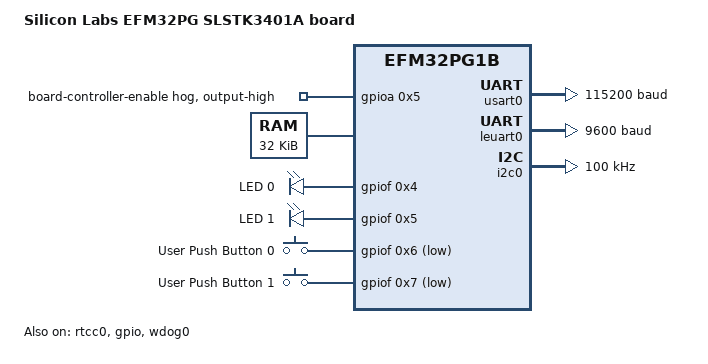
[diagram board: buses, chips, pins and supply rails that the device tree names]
/dts-v1/;

/* node '/' defined in zephyr/dts/common/skeleton.dtsi:9 */
/ {
	#address-cells = < 0x1 >;                        /* in zephyr/dts/common/skeleton.dtsi:10 */
	#size-cells = < 0x1 >;                           /* in zephyr/dts/common/skeleton.dtsi:11 */
	model = "Silicon Labs EFM32PG SLSTK3401A board"; /* in zephyr/boards/silabs/starter_kits/slstk3401a/slstk3401a.dts:12 */
	compatible = "silabs,slstk3401a",
	             "silabs,efm32pg1b";                 /* in zephyr/boards/silabs/starter_kits/slstk3401a/slstk3401a.dts:13 */

	/* node '/chosen' defined in zephyr/dts/common/skeleton.dtsi:13 */
	chosen {
		zephyr,flash-controller = &msc; /* in zephyr/dts/arm/silabs/xg1/xg1.dtsi:10 */
		zephyr,console = &usart0;       /* in zephyr/boards/silabs/starter_kits/slstk3401a/slstk3401a-common.dtsi:14 */
		zephyr,flash = &flash0;         /* in zephyr/boards/silabs/starter_kits/slstk3401a/slstk3401a-common.dtsi:15 */
		zephyr,shell-uart = &usart0;    /* in zephyr/boards/silabs/starter_kits/slstk3401a/slstk3401a-common.dtsi:16 */
		zephyr,sram = &sram0;           /* in zephyr/boards/silabs/starter_kits/slstk3401a/slstk3401a-common.dtsi:17 */
	};

	/* node '/aliases' defined in zephyr/dts/common/skeleton.dtsi:15 */
	aliases {
		led0 = &led0;       /* in zephyr/boards/silabs/starter_kits/slstk3401a/slstk3401a-common.dtsi:22 */
		led1 = &led1;       /* in zephyr/boards/silabs/starter_kits/slstk3401a/slstk3401a-common.dtsi:23 */
		sw0 = &button0;     /* in zephyr/boards/silabs/starter_kits/slstk3401a/slstk3401a-common.dtsi:24 */
		sw1 = &button1;     /* in zephyr/boards/silabs/starter_kits/slstk3401a/slstk3401a-common.dtsi:25 */
		watchdog0 = &wdog0; /* in zephyr/boards/silabs/starter_kits/slstk3401a/slstk3401a-common.dtsi:26 */
	};

	/* node '/soc' defined in zephyr/dts/arm/armv7-m.dtsi:6 */
	soc {
		#address-cells = < 0x1 >;                   /* in zephyr/dts/arm/armv7-m.dtsi:7 */
		#size-cells = < 0x1 >;                      /* in zephyr/dts/arm/armv7-m.dtsi:8 */
		interrupt-parent = < &nvic >;               /* in zephyr/dts/arm/armv7-m.dtsi:10 */
		ranges;                                     /* in zephyr/dts/arm/armv7-m.dtsi:11 */
		compatible = "silabs,efm32pg1b200f256gm48",
		             "silabs,efm32pg1b",
		             "silabs,efm32",
		             "simple-bus";                  /* in zephyr/dts/arm/silabs/xg1/efm32pg1b200f256gm48.dtsi:12 */

		/* node '/soc/interrupt-controller@e000e100' defined in zephyr/dts/arm/armv7-m.dtsi:13 */
		nvic: interrupt-controller@e000e100 {
			#address-cells = < 0x1 >;            /* in zephyr/dts/arm/armv7-m.dtsi:14 */
			compatible = "arm,v7m-nvic";         /* in zephyr/dts/arm/armv7-m.dtsi:15 */
			reg = < 0xe000e100 0xc00 >;          /* in zephyr/dts/arm/armv7-m.dtsi:16 */
			interrupt-controller;                /* in zephyr/dts/arm/armv7-m.dtsi:17 */
			#interrupt-cells = < 0x2 >;          /* in zephyr/dts/arm/armv7-m.dtsi:18 */
			arm,num-irq-priority-bits = < 0x3 >; /* in zephyr/dts/arm/silabs/xg1/xg1.dtsi:184 */
			phandle = < 0x1 >;                   /* in zephyr/dts/arm/armv7-m.dtsi:10 */
		};

		/* node '/soc/timer@e000e010' defined in zephyr/dts/arm/armv7-m.dtsi:21 */
		systick: timer@e000e010 {
			compatible = "arm,armv7m-systick"; /* in zephyr/dts/arm/armv7-m.dtsi:22 */
			reg = < 0xe000e010 0x10 >;         /* in zephyr/dts/arm/armv7-m.dtsi:23 */
		};

		/* node '/soc/flash-controller@400e0000' defined in zephyr/dts/arm/silabs/xg1/xg1.dtsi:28 */
		msc: flash-controller@400e0000 {
			compatible = "silabs,gecko-flash-controller"; /* in zephyr/dts/arm/silabs/xg1/xg1.dtsi:29 */
			reg = < 0x400e0000 0x800 >;                   /* in zephyr/dts/arm/silabs/xg1/xg1.dtsi:30 */
			interrupts = < 0x18 0x0 >;                    /* in zephyr/dts/arm/silabs/xg1/xg1.dtsi:31 */
			#address-cells = < 0x1 >;                     /* in zephyr/dts/arm/silabs/xg1/xg1.dtsi:33 */
			#size-cells = < 0x1 >;                        /* in zephyr/dts/arm/silabs/xg1/xg1.dtsi:34 */

			/* node '/soc/flash-controller@400e0000/flash@0' defined in zephyr/dts/arm/silabs/xg1/xg1.dtsi:36 */
			flash0: flash@0 {
				compatible = "soc-nv-flash";  /* in zephyr/dts/arm/silabs/xg1/xg1.dtsi:37 */
				write-block-size = < 0x4 >;   /* in zephyr/dts/arm/silabs/xg1/xg1.dtsi:38 */
				erase-block-size = < 0x800 >; /* in zephyr/dts/arm/silabs/xg1/xg1.dtsi:39 */
				reg = < 0x0 0x40000 >;        /* in zephyr/dts/arm/silabs/xg1/efm32pg1b200f256gm48.dtsi:17 */

				/* node '/soc/flash-controller@400e0000/flash@0/partitions' defined in zephyr/boards/silabs/starter_kits/slstk3401a/slstk3401a-common.dtsi:127 */
				partitions {
					compatible = "fixed-partitions"; /* in zephyr/boards/silabs/starter_kits/slstk3401a/slstk3401a-common.dtsi:128 */
					#address-cells = < 0x1 >;        /* in zephyr/boards/silabs/starter_kits/slstk3401a/slstk3401a-common.dtsi:129 */
					#size-cells = < 0x1 >;           /* in zephyr/boards/silabs/starter_kits/slstk3401a/slstk3401a-common.dtsi:130 */

					/* node '/soc/flash-controller@400e0000/flash@0/partitions/partition@3e800' defined in zephyr/boards/silabs/starter_kits/slstk3401a/slstk3401a-common.dtsi:133 */
					storage_partition: partition@3e800 {
						reg = < 0x3e800 0x1800 >; /* in zephyr/boards/silabs/starter_kits/slstk3401a/slstk3401a-common.dtsi:134 */
						label = "storage";        /* in zephyr/boards/silabs/starter_kits/slstk3401a/slstk3401a-common.dtsi:135 */
					};
				};
			};
		};

		/* node '/soc/usart@40010000' defined in zephyr/dts/arm/silabs/xg1/xg1.dtsi:43 */
		usart0: usart@40010000 {
			compatible = "silabs,gecko-usart"; /* in zephyr/dts/arm/silabs/xg1/xg1.dtsi:44 */
			reg = < 0x40010000 0x400 >;        /* in zephyr/dts/arm/silabs/xg1/xg1.dtsi:45 */
			interrupts = < 0xb 0x0 >,
			             < 0xc 0x0 >;          /* in zephyr/dts/arm/silabs/xg1/xg1.dtsi:46 */
			interrupt-names = "rx",
			                  "tx";            /* in zephyr/dts/arm/silabs/xg1/xg1.dtsi:47 */
			peripheral-id = < 0x0 >;           /* in zephyr/dts/arm/silabs/xg1/xg1.dtsi:48 */
			current-speed = < 0x1c200 >;       /* in zephyr/boards/silabs/starter_kits/slstk3401a/slstk3401a-common.dtsi:67 */
			pinctrl-0 = < &usart0_default >;   /* in zephyr/boards/silabs/starter_kits/slstk3401a/slstk3401a-common.dtsi:68 */
			pinctrl-names = "default";         /* in zephyr/boards/silabs/starter_kits/slstk3401a/slstk3401a-common.dtsi:69 */
			status = "okay";                   /* in zephyr/boards/silabs/starter_kits/slstk3401a/slstk3401a-common.dtsi:70 */
		};

		/* node '/soc/usart@40010400' defined in zephyr/dts/arm/silabs/xg1/xg1.dtsi:52 */
		usart1: usart@40010400 {
			compatible = "silabs,gecko-usart"; /* in zephyr/dts/arm/silabs/xg1/xg1.dtsi:53 */
			reg = < 0x40010400 0x400 >;        /* in zephyr/dts/arm/silabs/xg1/xg1.dtsi:54 */
			interrupts = < 0x13 0x0 >,
			             < 0x14 0x0 >;         /* in zephyr/dts/arm/silabs/xg1/xg1.dtsi:55 */
			interrupt-names = "rx",
			                  "tx";            /* in zephyr/dts/arm/silabs/xg1/xg1.dtsi:56 */
			peripheral-id = < 0x1 >;           /* in zephyr/dts/arm/silabs/xg1/xg1.dtsi:57 */
			status = "disabled";               /* in zephyr/dts/arm/silabs/xg1/xg1.dtsi:58 */
		};

		/* node '/soc/leuart@4004a000' defined in zephyr/dts/arm/silabs/xg1/xg1.dtsi:61 */
		leuart0: leuart@4004a000 {
			compatible = "silabs,gecko-leuart"; /* in zephyr/dts/arm/silabs/xg1/xg1.dtsi:62 */
			reg = < 0x4004a000 0x400 >;         /* in zephyr/dts/arm/silabs/xg1/xg1.dtsi:63 */
			interrupts = < 0x15 0x0 >;          /* in zephyr/dts/arm/silabs/xg1/xg1.dtsi:64 */
			peripheral-id = < 0x0 >;            /* in zephyr/dts/arm/silabs/xg1/xg1.dtsi:65 */
			current-speed = < 0x2580 >;         /* in zephyr/boards/silabs/starter_kits/slstk3401a/slstk3401a-common.dtsi:74 */
			location-rx = < 0x12 0x3 0xb >;     /* in zephyr/boards/silabs/starter_kits/slstk3401a/slstk3401a-common.dtsi:75 */
			location-tx = < 0x12 0x3 0xa >;     /* in zephyr/boards/silabs/starter_kits/slstk3401a/slstk3401a-common.dtsi:76 */
			status = "okay";                    /* in zephyr/boards/silabs/starter_kits/slstk3401a/slstk3401a-common.dtsi:77 */
		};

		/* node '/soc/i2c@4000c000' defined in zephyr/dts/arm/silabs/xg1/xg1.dtsi:69 */
		i2c0: i2c@4000c000 {
			compatible = "silabs,gecko-i2c"; /* in zephyr/dts/arm/silabs/xg1/xg1.dtsi:70 */
			clock-frequency = < 0x186a0 >;   /* in zephyr/dts/arm/silabs/xg1/xg1.dtsi:71 */
			#address-cells = < 0x1 >;        /* in zephyr/dts/arm/silabs/xg1/xg1.dtsi:72 */
			#size-cells = < 0x0 >;           /* in zephyr/dts/arm/silabs/xg1/xg1.dtsi:73 */
			reg = < 0x4000c000 0x400 >;      /* in zephyr/dts/arm/silabs/xg1/xg1.dtsi:74 */
			interrupts = < 0x10 0x0 >;       /* in zephyr/dts/arm/silabs/xg1/xg1.dtsi:75 */
			pinctrl-0 = < &i2c0_default >;   /* in zephyr/boards/silabs/starter_kits/slstk3401a/slstk3401a-common.dtsi:81 */
			pinctrl-names = "default";       /* in zephyr/boards/silabs/starter_kits/slstk3401a/slstk3401a-common.dtsi:82 */
			status = "okay";                 /* in zephyr/boards/silabs/starter_kits/slstk3401a/slstk3401a-common.dtsi:83 */
		};

		/* node '/soc/rtcc@40042000' defined in zephyr/dts/arm/silabs/xg1/xg1.dtsi:79 */
		rtcc0: rtcc@40042000 {
			compatible = "silabs,gecko-rtcc"; /* in zephyr/dts/arm/silabs/xg1/xg1.dtsi:80 */
			reg = < 0x40042000 0x184 >;       /* in zephyr/dts/arm/silabs/xg1/xg1.dtsi:81 */
			interrupts = < 0x1d 0x0 >;        /* in zephyr/dts/arm/silabs/xg1/xg1.dtsi:82 */
			clock-frequency = < 0x8000 >;     /* in zephyr/dts/arm/silabs/xg1/xg1.dtsi:83 */
			prescaler = < 0x1 >;              /* in zephyr/boards/silabs/starter_kits/slstk3401a/slstk3401a-common.dtsi:87 */
			status = "okay";                  /* in zephyr/boards/silabs/starter_kits/slstk3401a/slstk3401a-common.dtsi:88 */
		};

		/* node '/soc/gpio@4000a400' defined in zephyr/dts/arm/silabs/xg1/xg1.dtsi:88 */
		gpio: gpio@4000a400 {
			compatible = "silabs,gecko-gpio";  /* in zephyr/dts/arm/silabs/xg1/xg1.dtsi:89 */
			reg = < 0x4000a000 0x1000 >;       /* in zephyr/dts/arm/silabs/xg1/xg1.dtsi:90 */
			interrupts = < 0x9 0x2 0x11 0x2 >; /* in zephyr/dts/arm/silabs/xg1/xg1.dtsi:91 */
			interrupt-names = "GPIO_EVEN",
			                  "GPIO_ODD";      /* in zephyr/dts/arm/silabs/xg1/xg1.dtsi:92 */
			ranges;                            /* in zephyr/dts/arm/silabs/xg1/xg1.dtsi:94 */
			#address-cells = < 0x1 >;          /* in zephyr/dts/arm/silabs/xg1/xg1.dtsi:95 */
			#size-cells = < 0x1 >;             /* in zephyr/dts/arm/silabs/xg1/xg1.dtsi:96 */
			location-swo = < 0x0 >;            /* in zephyr/boards/silabs/starter_kits/slstk3401a/slstk3401a-common.dtsi:92 */
			status = "okay";                   /* in zephyr/boards/silabs/starter_kits/slstk3401a/slstk3401a-common.dtsi:93 */

			/* node '/soc/gpio@4000a400/gpio@4000a000' defined in zephyr/dts/arm/silabs/xg1/xg1.dtsi:98 */
			gpioa: gpio@4000a000 {
				compatible = "silabs,gecko-gpio-port"; /* in zephyr/dts/arm/silabs/xg1/xg1.dtsi:99 */
				reg = < 0x4000a000 0x30 >;             /* in zephyr/dts/arm/silabs/xg1/xg1.dtsi:100 */
				peripheral-id = < 0x0 >;               /* in zephyr/dts/arm/silabs/xg1/xg1.dtsi:101 */
				gpio-controller;                       /* in zephyr/dts/arm/silabs/xg1/xg1.dtsi:102 */
				#gpio-cells = < 0x2 >;                 /* in zephyr/dts/arm/silabs/xg1/xg1.dtsi:103 */
				status = "okay";                       /* in zephyr/boards/silabs/starter_kits/slstk3401a/slstk3401a-common.dtsi:97 */

				/* node '/soc/gpio@4000a400/gpio@4000a000/board-controller-enable' defined in zephyr/boards/silabs/starter_kits/slstk3401a/slstk3401a-common.dtsi:99 */
				board-controller-enable {
					gpio-hog;            /* in zephyr/boards/silabs/starter_kits/slstk3401a/slstk3401a-common.dtsi:100 */
					gpios = < 0x5 0x0 >; /* in zephyr/boards/silabs/starter_kits/slstk3401a/slstk3401a-common.dtsi:101 */
					output-high;         /* in zephyr/boards/silabs/starter_kits/slstk3401a/slstk3401a-common.dtsi:102 */
				};
			};

			/* node '/soc/gpio@4000a400/gpio@4000a030' defined in zephyr/dts/arm/silabs/xg1/xg1.dtsi:107 */
			gpiob: gpio@4000a030 {
				compatible = "silabs,gecko-gpio-port"; /* in zephyr/dts/arm/silabs/xg1/xg1.dtsi:108 */
				reg = < 0x4000a030 0x30 >;             /* in zephyr/dts/arm/silabs/xg1/xg1.dtsi:109 */
				peripheral-id = < 0x1 >;               /* in zephyr/dts/arm/silabs/xg1/xg1.dtsi:110 */
				gpio-controller;                       /* in zephyr/dts/arm/silabs/xg1/xg1.dtsi:111 */
				#gpio-cells = < 0x2 >;                 /* in zephyr/dts/arm/silabs/xg1/xg1.dtsi:112 */
				status = "okay";                       /* in zephyr/boards/silabs/starter_kits/slstk3401a/slstk3401a-common.dtsi:107 */
			};

			/* node '/soc/gpio@4000a400/gpio@4000a060' defined in zephyr/dts/arm/silabs/xg1/xg1.dtsi:116 */
			gpioc: gpio@4000a060 {
				compatible = "silabs,gecko-gpio-port"; /* in zephyr/dts/arm/silabs/xg1/xg1.dtsi:117 */
				reg = < 0x4000a060 0x30 >;             /* in zephyr/dts/arm/silabs/xg1/xg1.dtsi:118 */
				peripheral-id = < 0x2 >;               /* in zephyr/dts/arm/silabs/xg1/xg1.dtsi:119 */
				gpio-controller;                       /* in zephyr/dts/arm/silabs/xg1/xg1.dtsi:120 */
				#gpio-cells = < 0x2 >;                 /* in zephyr/dts/arm/silabs/xg1/xg1.dtsi:121 */
				status = "okay";                       /* in zephyr/boards/silabs/starter_kits/slstk3401a/slstk3401a-common.dtsi:111 */
			};

			/* node '/soc/gpio@4000a400/gpio@4000a090' defined in zephyr/dts/arm/silabs/xg1/xg1.dtsi:125 */
			gpiod: gpio@4000a090 {
				compatible = "silabs,gecko-gpio-port"; /* in zephyr/dts/arm/silabs/xg1/xg1.dtsi:126 */
				reg = < 0x4000a090 0x30 >;             /* in zephyr/dts/arm/silabs/xg1/xg1.dtsi:127 */
				peripheral-id = < 0x3 >;               /* in zephyr/dts/arm/silabs/xg1/xg1.dtsi:128 */
				gpio-controller;                       /* in zephyr/dts/arm/silabs/xg1/xg1.dtsi:129 */
				#gpio-cells = < 0x2 >;                 /* in zephyr/dts/arm/silabs/xg1/xg1.dtsi:130 */
				status = "okay";                       /* in zephyr/boards/silabs/starter_kits/slstk3401a/slstk3401a-common.dtsi:115 */
			};

			/* node '/soc/gpio@4000a400/gpio@4000a0c0' defined in zephyr/dts/arm/silabs/xg1/xg1.dtsi:134 */
			gpioe: gpio@4000a0c0 {
				compatible = "silabs,gecko-gpio-port"; /* in zephyr/dts/arm/silabs/xg1/xg1.dtsi:135 */
				reg = < 0x4000a0c0 0x30 >;             /* in zephyr/dts/arm/silabs/xg1/xg1.dtsi:136 */
				peripheral-id = < 0x4 >;               /* in zephyr/dts/arm/silabs/xg1/xg1.dtsi:137 */
				gpio-controller;                       /* in zephyr/dts/arm/silabs/xg1/xg1.dtsi:138 */
				#gpio-cells = < 0x2 >;                 /* in zephyr/dts/arm/silabs/xg1/xg1.dtsi:139 */
				status = "disabled";                   /* in zephyr/dts/arm/silabs/xg1/xg1.dtsi:140 */
			};

			/* node '/soc/gpio@4000a400/gpio@4000a0f0' defined in zephyr/dts/arm/silabs/xg1/xg1.dtsi:143 */
			gpiof: gpio@4000a0f0 {
				compatible = "silabs,gecko-gpio-port"; /* in zephyr/dts/arm/silabs/xg1/xg1.dtsi:144 */
				reg = < 0x4000a0f0 0x30 >;             /* in zephyr/dts/arm/silabs/xg1/xg1.dtsi:145 */
				peripheral-id = < 0x5 >;               /* in zephyr/dts/arm/silabs/xg1/xg1.dtsi:146 */
				gpio-controller;                       /* in zephyr/dts/arm/silabs/xg1/xg1.dtsi:147 */
				#gpio-cells = < 0x2 >;                 /* in zephyr/dts/arm/silabs/xg1/xg1.dtsi:148 */
				status = "okay";                       /* in zephyr/boards/silabs/starter_kits/slstk3401a/slstk3401a-common.dtsi:119 */
				phandle = < 0x4 >;                     /* in zephyr/boards/silabs/starter_kits/slstk3401a/slstk3401a-common.dtsi:33 */
			};
		};

		/* node '/soc/wdog@40052000' defined in zephyr/dts/arm/silabs/xg1/xg1.dtsi:153 */
		wdog0: wdog@40052000 {
			compatible = "silabs,gecko-wdog"; /* in zephyr/dts/arm/silabs/xg1/xg1.dtsi:154 */
			reg = < 0x40052000 0x400 >;       /* in zephyr/dts/arm/silabs/xg1/xg1.dtsi:155 */
			peripheral-id = < 0x0 >;          /* in zephyr/dts/arm/silabs/xg1/xg1.dtsi:156 */
			interrupts = < 0x2 0x0 >;         /* in zephyr/dts/arm/silabs/xg1/xg1.dtsi:157 */
			status = "okay";                  /* in zephyr/boards/silabs/starter_kits/slstk3401a/slstk3401a-common.dtsi:123 */
		};

		/* node '/soc/timer@40018000' defined in zephyr/dts/arm/silabs/xg1/xg1.dtsi:161 */
		timer0: timer@40018000 {
			compatible = "silabs,gecko-timers"; /* in zephyr/dts/arm/silabs/xg1/xg1.dtsi:162 */
			reg = < 0x40018000 0x400 >;         /* in zephyr/dts/arm/silabs/xg1/xg1.dtsi:163 */
			status = "disabled";                /* in zephyr/dts/arm/silabs/xg1/xg1.dtsi:164 */

			/* node '/soc/timer@40018000/pwm' defined in zephyr/dts/arm/silabs/xg1/xg1.dtsi:166 */
			pwm {
				compatible = "silabs,gecko-pwm"; /* in zephyr/dts/arm/silabs/xg1/xg1.dtsi:167 */
				status = "disabled";             /* in zephyr/dts/arm/silabs/xg1/xg1.dtsi:168 */
				#pwm-cells = < 0x3 >;            /* in zephyr/dts/arm/silabs/xg1/xg1.dtsi:169 */
			};
		};
	};

	/* node '/cpus' defined in zephyr/dts/arm/silabs/xg1/xg1.dtsi:13 */
	cpus {
		#address-cells = < 0x1 >; /* in zephyr/dts/arm/silabs/xg1/xg1.dtsi:14 */
		#size-cells = < 0x0 >;    /* in zephyr/dts/arm/silabs/xg1/xg1.dtsi:15 */

		/* node '/cpus/cpu@0' defined in zephyr/dts/arm/silabs/xg1/xg1.dtsi:17 */
		cpu0: cpu@0 {
			compatible = "arm,cortex-m4f";   /* in zephyr/dts/arm/silabs/xg1/xg1.dtsi:18 */
			reg = < 0x0 >;                   /* in zephyr/dts/arm/silabs/xg1/xg1.dtsi:19 */
			clock-frequency = < 0x2625a00 >; /* in zephyr/boards/silabs/starter_kits/slstk3401a/slstk3401a-common.dtsi:63 */
		};
	};

	/* node '/memory@20000000' defined in zephyr/dts/arm/silabs/xg1/xg1.dtsi:23 */
	sram0: memory@20000000 {
		compatible = "mmio-sram";    /* in zephyr/dts/arm/silabs/xg1/xg1.dtsi:24 */
		reg = < 0x20000000 0x8000 >; /* in zephyr/dts/arm/silabs/xg1/efm32pg1b200f256gm48.dtsi:21 */
	};

	/* node '/pin-controller' defined in zephyr/dts/arm/silabs/xg1/xg1.dtsi:174 */
	pinctrl: pin-controller {
		compatible = "silabs,gecko-pinctrl"; /* in zephyr/dts/arm/silabs/xg1/xg1.dtsi:179 */

		/* node '/pin-controller/i2c0_default' defined in zephyr/boards/silabs/starter_kits/slstk3401a/slstk3401a-pinctrl.dtsi:10 */
		i2c0_default: i2c0_default {
			phandle = < 0x3 >; /* in zephyr/boards/silabs/starter_kits/slstk3401a/slstk3401a-common.dtsi:81 */

			/* node '/pin-controller/i2c0_default/group1' defined in zephyr/boards/silabs/starter_kits/slstk3401a/slstk3401a-pinctrl.dtsi:11 */
			group1 {
				psels = < 0x1600020a >,
				        < 0x1700020b >,
				        < 0x1800000f >,
				        < 0x1900000f >; /* in zephyr/boards/silabs/starter_kits/slstk3401a/slstk3401a-pinctrl.dtsi:12 */
			};
		};

		/* node '/pin-controller/usart0_default' defined in zephyr/boards/silabs/starter_kits/slstk3401a/slstk3401a-pinctrl.dtsi:20 */
		usart0_default: usart0_default {
			phandle = < 0x2 >; /* in zephyr/boards/silabs/starter_kits/slstk3401a/slstk3401a-common.dtsi:68 */

			/* node '/pin-controller/usart0_default/group1' defined in zephyr/boards/silabs/starter_kits/slstk3401a/slstk3401a-pinctrl.dtsi:21 */
			group1 {
				psels = < 0x0 >,
				        < 0x1000001 >,
				        < 0x5000000 >,
				        < 0x4000001 >; /* in zephyr/boards/silabs/starter_kits/slstk3401a/slstk3401a-pinctrl.dtsi:22 */
			};
		};
	};

	/* node '/leds' defined in zephyr/boards/silabs/starter_kits/slstk3401a/slstk3401a-common.dtsi:29 */
	leds {
		compatible = "gpio-leds"; /* in zephyr/boards/silabs/starter_kits/slstk3401a/slstk3401a-common.dtsi:30 */

		/* node '/leds/led_0' defined in zephyr/boards/silabs/starter_kits/slstk3401a/slstk3401a-common.dtsi:32 */
		led0: led_0 {
			gpios = < &gpiof 0x4 0x0 >; /* in zephyr/boards/silabs/starter_kits/slstk3401a/slstk3401a-common.dtsi:33 */
			label = "LED 0";            /* in zephyr/boards/silabs/starter_kits/slstk3401a/slstk3401a-common.dtsi:34 */
		};

		/* node '/leds/led_1' defined in zephyr/boards/silabs/starter_kits/slstk3401a/slstk3401a-common.dtsi:37 */
		led1: led_1 {
			gpios = < &gpiof 0x5 0x0 >; /* in zephyr/boards/silabs/starter_kits/slstk3401a/slstk3401a-common.dtsi:38 */
			label = "LED 1";            /* in zephyr/boards/silabs/starter_kits/slstk3401a/slstk3401a-common.dtsi:39 */
		};
	};

	/* node '/buttons' defined in zephyr/boards/silabs/starter_kits/slstk3401a/slstk3401a-common.dtsi:43 */
	buttons {
		compatible = "gpio-keys"; /* in zephyr/boards/silabs/starter_kits/slstk3401a/slstk3401a-common.dtsi:44 */

		/* node '/buttons/button_0' defined in zephyr/boards/silabs/starter_kits/slstk3401a/slstk3401a-common.dtsi:46 */
		button0: button_0 {
			gpios = < &gpiof 0x6 0x1 >;   /* in zephyr/boards/silabs/starter_kits/slstk3401a/slstk3401a-common.dtsi:48 */
			label = "User Push Button 0"; /* in zephyr/boards/silabs/starter_kits/slstk3401a/slstk3401a-common.dtsi:49 */
			zephyr,code = < 0xb >;        /* in zephyr/boards/silabs/starter_kits/slstk3401a/slstk3401a-common.dtsi:50 */
		};

		/* node '/buttons/button_1' defined in zephyr/boards/silabs/starter_kits/slstk3401a/slstk3401a-common.dtsi:53 */
		button1: button_1 {
			gpios = < &gpiof 0x7 0x1 >;   /* in zephyr/boards/silabs/starter_kits/slstk3401a/slstk3401a-common.dtsi:55 */
			label = "User Push Button 1"; /* in zephyr/boards/silabs/starter_kits/slstk3401a/slstk3401a-common.dtsi:56 */
			zephyr,code = < 0x2 >;        /* in zephyr/boards/silabs/starter_kits/slstk3401a/slstk3401a-common.dtsi:57 */
		};
	};
};
